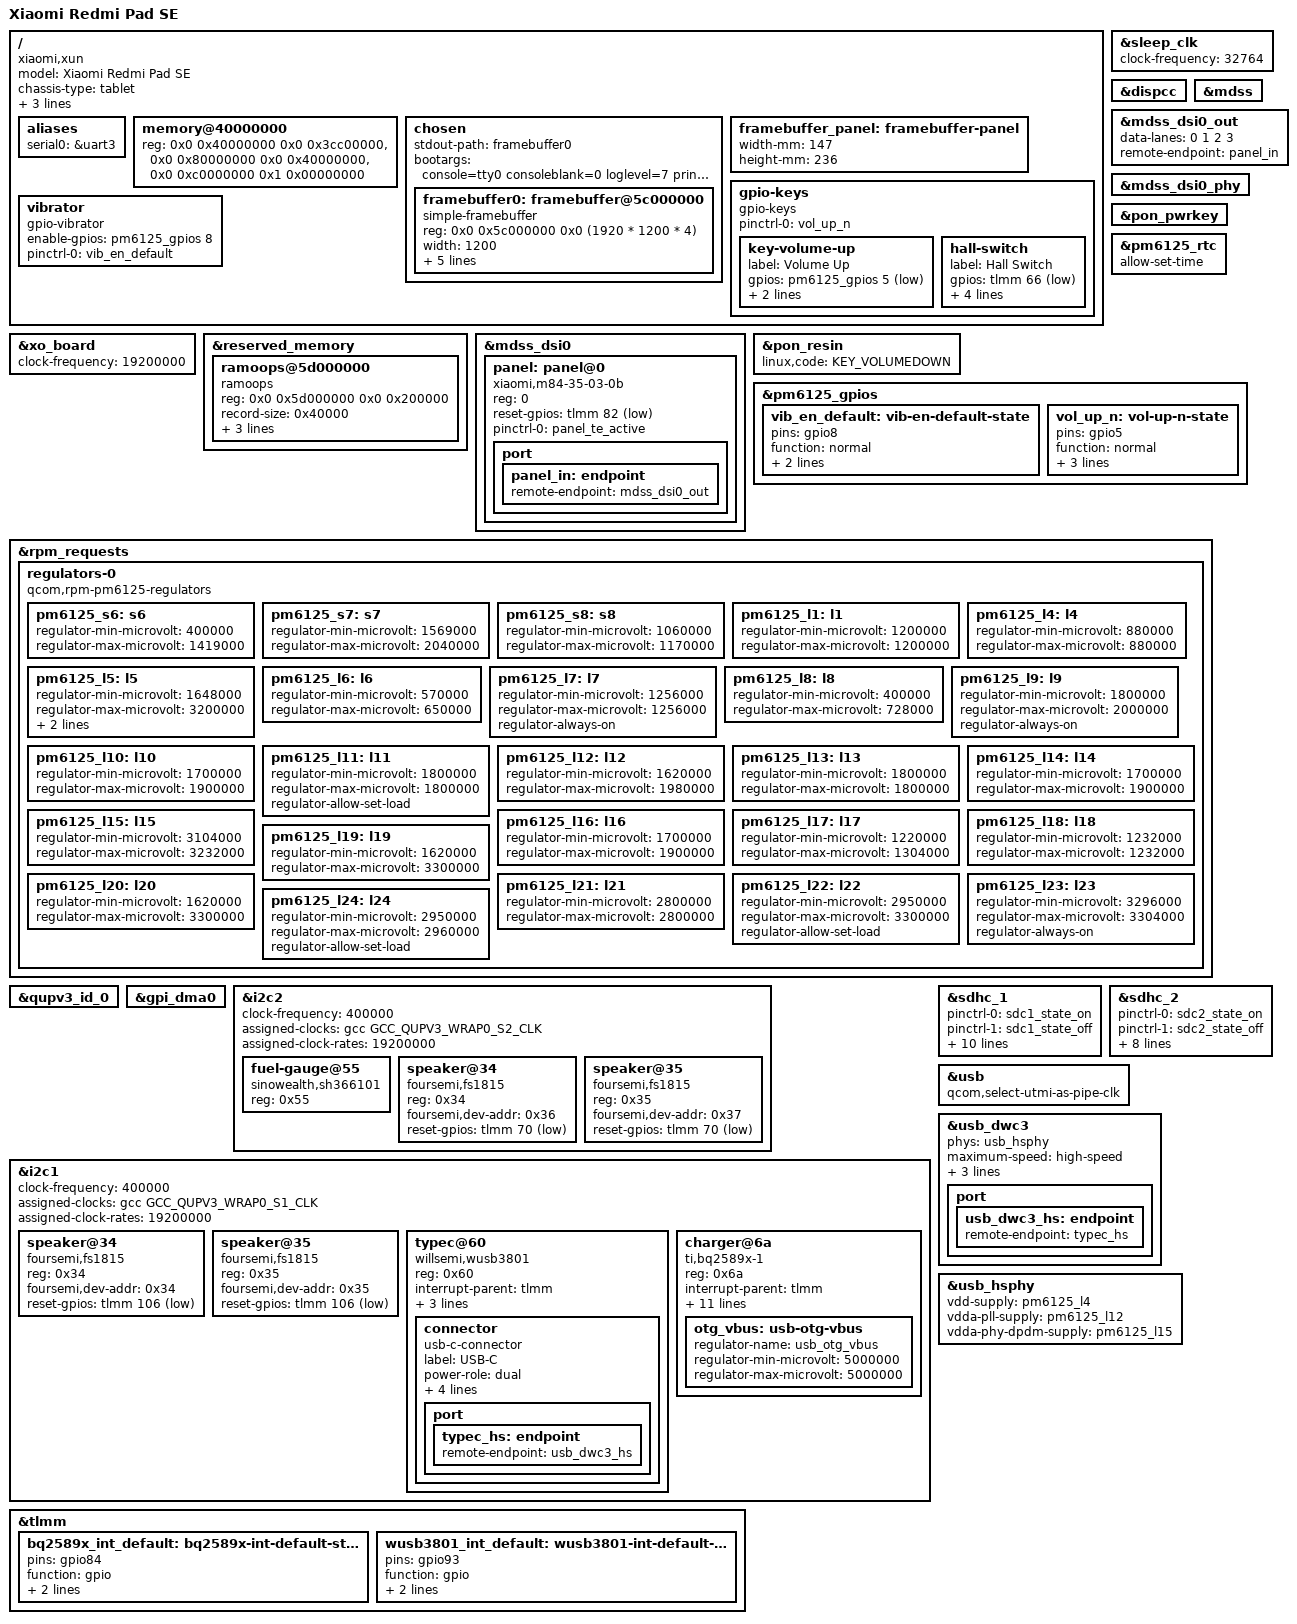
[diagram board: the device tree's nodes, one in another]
// SPDX-License-Identifier: GPL-2.0-only
/*
 * Xiaomi Redmi Pad SE 11" (xun), SM6225 "Khaje".
 *
 * Layout follows the Redmi Note 12 4G (tapas) board file, which shares the
 * SoC, PMIC and most of the board with xun. The differences come from the
 * stock xun device tree (docs/reference/xun-merged.dts) and from the live
 * device: eMMC instead of UFS, the FT8203 touch controller on SPI, the M84
 * panel family, and the WCN3990 Wi-Fi/BT combo.
 *
 * The bootloader does not see this DTB (the shim passes it), so the memory
 * node is the layout ABL reports for the 6 GB unit.
 */
/dts-v1/;
#include "sm6225.dtsi"
#include "pm6125.dtsi"
#include <dt-bindings/gpio/gpio.h>
#include <dt-bindings/interrupt-controller/irq.h>
#include <dt-bindings/input/linux-event-codes.h>
#include <dt-bindings/soc/qcom,gpr.h>
#include <dt-bindings/sound/qcom,q6afe.h>
#include <dt-bindings/sound/qcom,q6dsp-lpass-ports.h>

/delete-node/ &{/memory@80000000};

/ {
	model = "Xiaomi Redmi Pad SE";
	compatible = "xiaomi,xun", "qcom,sm6225";
	chassis-type = "tablet";

	qcom,msm-id = <0x206 0x10000>;
	qcom,board-id = <0x20022 0x00>;
	qcom,pmic-id = <0x2d 0x00 0x00 0x00>;

	aliases {
		serial0 = &uart3;
	};

	/* ABL "RAM Partitions": 2 GB rank 0 + 4 GB rank 1 */
	memory@40000000 {
		device_type = "memory";
		reg = <0x0 0x40000000 0x0 0x3cc00000>,
		      <0x0 0x80000000 0x0 0x40000000>,
		      <0x0 0xc0000000 0x1 0x00000000>;
	};

	chosen {
		#address-cells = <2>;
		#size-cells = <2>;
		ranges;
		stdout-path = "framebuffer0";
		/*
		 * The native 1200x1920 panel is mounted in portrait orientation
		 * inside the tablet's landscape chassis. Report the panel's
		 * left-side-up mounting so Mutter starts in landscape and applies
		 * the matching input transform to the touchscreen.
		 */
		bootargs = "console=tty0 consoleblank=0 loglevel=7 printk.devkmsg=on log_buf_len=2M clk_ignore_unused pd_ignore_unused fw_devlink=off deferred_probe_timeout=120 rcupdate.rcu_cpu_stall_suppress=1 video=DSI-1:panel_orientation=left_side_up";

		/* 1200x1920, 32 bpp: the splash buffer ABL scans out */
		framebuffer0: framebuffer@5c000000 {
			compatible = "simple-framebuffer";
			reg = <0x0 0x5c000000 0x0 (1920 * 1200 * 4)>;
			width = <1200>;
			height = <1920>;
			stride = <(1200 * 4)>;
			format = "a8r8g8b8";
			refresh-rate = <90>;
			panel = <&framebuffer_panel>;
		};
	};

	/* 147.4 x 235.8 mm active area (stock qcom,mdss-pan-physical-*-dimension / 10) */
	framebuffer_panel: framebuffer-panel {
		width-mm = <147>;
		height-mm = <236>;
	};

	gpio-keys {
		compatible = "gpio-keys";
		pinctrl-names = "default";
		pinctrl-0 = <&vol_up_n>;

		key-volume-up {
			label = "Volume Up";
			gpios = <&pm6125_gpios 5 GPIO_ACTIVE_LOW>;
			linux,code = <KEY_VOLUMEUP>;
			debounce-interval = <15>;
		};

		/* Stock hall_key: lid/cover switch on TLMM GPIO66 */
		hall-switch {
			label = "Hall Switch";
			gpios = <&tlmm 66 GPIO_ACTIVE_LOW>;
			linux,input-type = <EV_SW>;
			linux,code = <SW_LID>;
			wakeup-source;
			debounce-interval = <15>;
		};
	};

	/* Stock vibrator_gpio: the motor runs while PM6125 GPIO8 is high */
	vibrator {
		compatible = "gpio-vibrator";
		enable-gpios = <&pm6125_gpios 8 GPIO_ACTIVE_HIGH>;
		pinctrl-0 = <&vib_en_default>;
		pinctrl-names = "default";
	};
};

&xo_board {
	clock-frequency = <19200000>;
};

&sleep_clk {
	clock-frequency = <32764>;
};

&reserved_memory {
	ramoops@5d000000 {
		compatible = "ramoops";
		reg = <0x0 0x5d000000 0x0 0x200000>;
		record-size = <0x40000>;
		pmsg-size = <0x100000>;
		console-size = <0x80000>;
		no-map;
	};
};

/* The splash scanout depends on the dispcc PLL rates ABL programmed */
&dispcc {
	status = "okay";
};

/* DPU + DSI + the M84 panel */
&mdss {
	status = "okay";
};

&mdss_dsi0 {
	status = "okay";

	panel: panel@0 {
		compatible = "xiaomi,m84-35-03-0b";
		reg = <0>;

		reset-gpios = <&tlmm 82 GPIO_ACTIVE_LOW>;

		pinctrl-0 = <&panel_te_active>;
		pinctrl-names = "default";

		port {
			panel_in: endpoint {
				remote-endpoint = <&mdss_dsi0_out>;
			};
		};
	};
};

&mdss_dsi0_out {
	data-lanes = <0 1 2 3>;
	remote-endpoint = <&panel_in>;
};

&mdss_dsi0_phy {
	status = "okay";
};

&pon_pwrkey {
	status = "okay";
};

&pon_resin {
	linux,code = <KEY_VOLUMEDOWN>;
	status = "okay";
};

&pm6125_rtc {
	allow-set-time;
	status = "okay";
};

&pm6125_gpios {
	vib_en_default: vib-en-default-state {
		pins = "gpio8";
		function = "normal";
		power-source = <0>;
		output-low;
	};

	vol_up_n: vol-up-n-state {
		pins = "gpio5";
		function = "normal";
		power-source = <0>;
		bias-pull-up;
		input-enable;
	};
};

&rpm_requests {
	regulators-0 {
		compatible = "qcom,rpm-pm6125-regulators";

		pm6125_s6: s6 {
			regulator-min-microvolt = <400000>;
			regulator-max-microvolt = <1419000>;
		};

		pm6125_s7: s7 {
			regulator-min-microvolt = <1569000>;
			regulator-max-microvolt = <2040000>;
		};

		pm6125_s8: s8 {
			regulator-min-microvolt = <1060000>;
			regulator-max-microvolt = <1170000>;
		};

		/* camera dvdd (stock cam_vdig) */
		pm6125_l1: l1 {
			regulator-min-microvolt = <1200000>;
			regulator-max-microvolt = <1200000>;
		};

		/* USB PHY */
		pm6125_l4: l4 {
			regulator-min-microvolt = <880000>;
			regulator-max-microvolt = <880000>;
		};

		/* eMMC / SD card I/O */
		pm6125_l5: l5 {
			regulator-min-microvolt = <1648000>;
			regulator-max-microvolt = <3200000>;
			regulator-allow-set-load;
			regulator-always-on;
		};

		pm6125_l6: l6 {
			regulator-min-microvolt = <570000>;
			regulator-max-microvolt = <650000>;
		};

		pm6125_l7: l7 {
			regulator-min-microvolt = <1256000>;
			regulator-max-microvolt = <1256000>;
			regulator-always-on;
		};

		pm6125_l8: l8 {
			regulator-min-microvolt = <400000>;
			regulator-max-microvolt = <728000>;
		};

		/* Touch I/O and Wi-Fi/BT I/O (stock vdd-io / vddio) */
		pm6125_l9: l9 {
			regulator-min-microvolt = <1800000>;
			regulator-max-microvolt = <2000000>;
			regulator-always-on;
		};

		pm6125_l10: l10 {
			regulator-min-microvolt = <1700000>;
			regulator-max-microvolt = <1900000>;
		};

		/* eMMC VCCQ2 (stock qcom,vdd-io-voltage-level 1.8 V) */
		pm6125_l11: l11 {
			regulator-min-microvolt = <1800000>;
			regulator-max-microvolt = <1800000>;
			regulator-allow-set-load;
		};

		/* USB PHY PLL */
		pm6125_l12: l12 {
			regulator-min-microvolt = <1620000>;
			regulator-max-microvolt = <1980000>;
		};

		/* camera dovdd (stock cam_vio) */
		pm6125_l13: l13 {
			regulator-min-microvolt = <1800000>;
			regulator-max-microvolt = <1800000>;
		};

		pm6125_l14: l14 {
			regulator-min-microvolt = <1700000>;
			regulator-max-microvolt = <1900000>;
		};

		/* USB PHY D+/D- */
		pm6125_l15: l15 {
			regulator-min-microvolt = <3104000>;
			regulator-max-microvolt = <3232000>;
		};

		/* Wi-Fi/BT xtal rail (stock qcom,bt-vdd-xtal) */
		pm6125_l16: l16 {
			regulator-min-microvolt = <1700000>;
			regulator-max-microvolt = <1900000>;
		};

		/* Wi-Fi/BT core rail (stock qcom,bt-vdd-core) */
		pm6125_l17: l17 {
			regulator-min-microvolt = <1220000>;
			regulator-max-microvolt = <1304000>;
		};

		pm6125_l18: l18 {
			regulator-min-microvolt = <1232000>;
			regulator-max-microvolt = <1232000>;
		};

		pm6125_l19: l19 {
			regulator-min-microvolt = <1620000>;
			regulator-max-microvolt = <3300000>;
		};

		pm6125_l20: l20 {
			regulator-min-microvolt = <1620000>;
			regulator-max-microvolt = <3300000>;
		};

		/* camera avdd (stock cam_vana) */
		pm6125_l21: l21 {
			regulator-min-microvolt = <2800000>;
			regulator-max-microvolt = <2800000>;
		};

		/* SD card VCC (stock vdd-supply of sdhc_2) */
		pm6125_l22: l22 {
			regulator-min-microvolt = <2950000>;
			regulator-max-microvolt = <3300000>;
			regulator-allow-set-load;
		};

		/* Wi-Fi/BT PA rail (stock qcom,bt-vdd-pa) */
		pm6125_l23: l23 {
			regulator-min-microvolt = <3296000>;
			regulator-max-microvolt = <3304000>;
			regulator-always-on;
		};

		/* eMMC VCC (stock qcom,vdd-voltage-level 2.95 V) */
		pm6125_l24: l24 {
			regulator-min-microvolt = <2950000>;
			regulator-max-microvolt = <2960000>;
			regulator-allow-set-load;
		};
	};
};

&qupv3_id_0 {
	status = "okay";
};

&gpi_dma0 {
	status = "okay";
};

/* Fuel gauge: the SH366101 tracks the battery on its own */
&i2c2 {
	status = "okay";
	clock-frequency = <400000>;
	assigned-clocks = <&gcc GCC_QUPV3_WRAP0_S2_CLK>;
	assigned-clock-rates = <19200000>;

	fuel-gauge@55 {
		compatible = "sinowealth,sh366101";
		reg = <0x55>;
	};

	/* Second speaker pair; the reset line is shared with its sibling */
	speaker@34 {
		compatible = "foursemi,fs1815";
		reg = <0x34>;
		foursemi,dev-addr = <0x36>;
		reset-gpios = <&tlmm 70 GPIO_ACTIVE_LOW>;
	};

	speaker@35 {
		compatible = "foursemi,fs1815";
		reg = <0x35>;
		foursemi,dev-addr = <0x37>;
		reset-gpios = <&tlmm 70 GPIO_ACTIVE_LOW>;
	};
};

/* First speaker pair */
&i2c1 {
	status = "okay";
	clock-frequency = <400000>;
	assigned-clocks = <&gcc GCC_QUPV3_WRAP0_S1_CLK>;
	assigned-clock-rates = <19200000>;

	speaker@34 {
		compatible = "foursemi,fs1815";
		reg = <0x34>;
		foursemi,dev-addr = <0x34>;
		reset-gpios = <&tlmm 106 GPIO_ACTIVE_LOW>;
	};

	speaker@35 {
		compatible = "foursemi,fs1815";
		reg = <0x35>;
		foursemi,dev-addr = <0x35>;
		reset-gpios = <&tlmm 106 GPIO_ACTIVE_LOW>;
	};

	/*
	 * WUSB3801 Type-C port controller.  It reports the current
	 * advertised on CC, which lets a PD-only charger run at 5 V/3 A
	 * even though the tablet cannot negotiate PD.
	 *
	 * Graph port links the connector to DWC3 so role-switch works.
	 */
	typec@60 {
		compatible = "willsemi,wusb3801";
		reg = <0x60>;

		interrupt-parent = <&tlmm>;
		interrupts = <93 IRQ_TYPE_LEVEL_LOW>;
		pinctrl-names = "default";
		pinctrl-0 = <&wusb3801_int_default>;

		vbus-supply = <&otg_vbus>;

		connector {
			compatible = "usb-c-connector";
			label = "USB-C";
			power-role = "dual";
			try-power-role = "sink";
			data-role = "dual";
			typec-power-opmode = "default";
			pd-disable;

			port {
				typec_hs: endpoint {
					remote-endpoint = <&usb_dwc3_hs>;
				};
			};
		};
	};

	/* BQ2589X charger (register compatible with the BQ25890 driver) */
	charger@6a {
		compatible = "ti,bq2589x-1";
		reg = <0x6a>;

		interrupt-parent = <&tlmm>;
		interrupts = <84 IRQ_TYPE_EDGE_FALLING>;
		pinctrl-names = "default";
		pinctrl-0 = <&bq2589x_int_default>;

		/* 18 W fast charge: 9 V / 2 A in, 3.6 A into the cell */
		ti,charge-current = <3600000>;
		ti,battery-regulation-voltage = <4450000>;
		ti,termination-current = <450000>;
		ti,precharge-current = <128000>;
		ti,minimum-sys-voltage = <3500000>;
		ti,boost-voltage = <5000000>;
		ti,boost-max-current = <1500000>;
		ti,enable-auto-dpdm;
		ti,enable-termination;
		/*
		 * The BQ2589X boost converter supplies VBUS in host mode.
		 * WUSB3801 enables it when a downstream USB device is attached.
		 */
		otg_vbus: usb-otg-vbus {
			regulator-name = "usb_otg_vbus";
			regulator-min-microvolt = <5000000>;
			regulator-max-microvolt = <5000000>;
		};
	};
};

&tlmm {
	bq2589x_int_default: bq2589x-int-default-state {
		pins = "gpio84";
		function = "gpio";
		drive-strength = <2>;
		bias-pull-up;
	};

	wusb3801_int_default: wusb3801-int-default-state {
		pins = "gpio93";
		function = "gpio";
		drive-strength = <2>;
		bias-pull-up;
	};
};

/* eMMC: the boot medium (mmcblk0), 8 bits, HS200/HS400 */
&sdhc_1 {
	pinctrl-names = "default", "sleep";
	pinctrl-0 = <&sdc1_state_on>;
	pinctrl-1 = <&sdc1_state_off>;

	vmmc-supply = <&pm6125_l24>;
	vqmmc-supply = <&pm6125_l11>;

	bus-width = <8>;
	non-removable;
	no-sd;
	no-sdio;
	mmc-ddr-1_8v;
	mmc-hs200-1_8v;
	mmc-hs400-1_8v;
	mmc-hs400-enhanced-strobe;
	status = "okay";
};

/* microSD, card detect on GPIO88 */
&sdhc_2 {
	pinctrl-names = "default", "sleep";
	pinctrl-0 = <&sdc2_state_on>;
	pinctrl-1 = <&sdc2_state_off>;

	vmmc-supply = <&pm6125_l22>;
	vqmmc-supply = <&pm6125_l5>;

	bus-width = <4>;
	no-sdio;
	no-mmc;
	qcom,ddr-config = <0x80040868>;
	sdhci-caps-mask = <0x00000002 0x00000000>;
	cd-gpios = <&tlmm 88 GPIO_ACTIVE_LOW>;
	status = "okay";
};

&usb {
	qcom,select-utmi-as-pipe-clk;
	status = "okay";
};

&usb_dwc3 {
	phys = <&usb_hsphy>;
	phy-names = "usb2-phy";
	maximum-speed = "high-speed";
	/*
	 * Dual-role. Default to host so OTG (keyboard/mouse) works immediately
	 * while touch is still broken. The Type-C graph + role-sync daemon can
	 * still switch back to peripheral for NCM/ACM when needed.
	 */
	dr_mode = "otg";
	usb-role-switch;
	role-switch-default-mode = "host";

	port {
		usb_dwc3_hs: endpoint {
			remote-endpoint = <&typec_hs>;
		};
	};
};

&usb_hsphy {
	vdd-supply = <&pm6125_l4>;
	vdda-pll-supply = <&pm6125_l12>;
	vdda-phy-dpdm-supply = <&pm6125_l15>;
	status = "okay";
};
